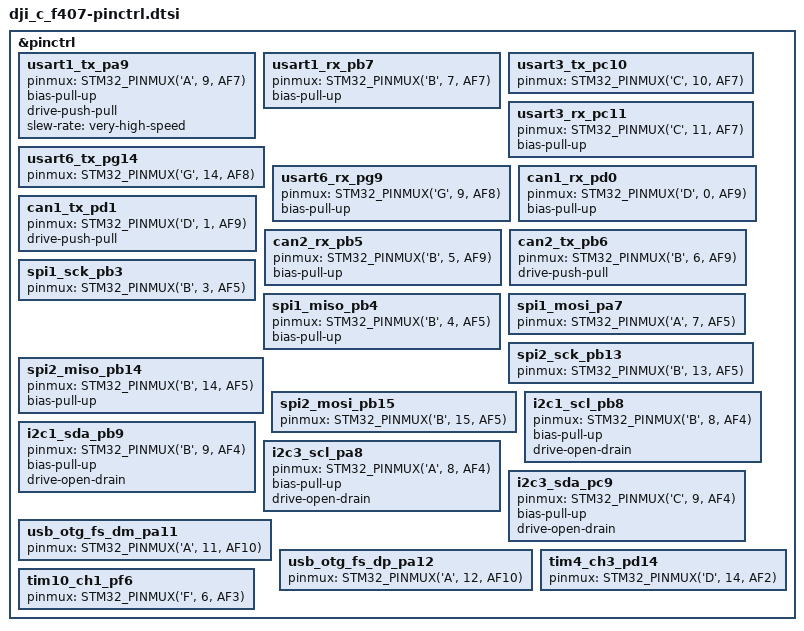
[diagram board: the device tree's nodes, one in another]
/* SPDX-License-Identifier: Apache-2.0 */

#include <zephyr/dt-bindings/pinctrl/stm32-pinctrl.h>

&pinctrl {
	usart1_tx_pa9: usart1_tx_pa9 {
		pinmux = <STM32_PINMUX('A', 9, AF7)>;
		bias-pull-up;
		drive-push-pull;
		slew-rate = "very-high-speed";
	};

	usart1_rx_pb7: usart1_rx_pb7 {
		pinmux = <STM32_PINMUX('B', 7, AF7)>;
		bias-pull-up;
	};

	usart3_tx_pc10: usart3_tx_pc10 { pinmux = <STM32_PINMUX('C', 10, AF7)>; };
	usart3_rx_pc11: usart3_rx_pc11 { pinmux = <STM32_PINMUX('C', 11, AF7)>; bias-pull-up; };
	usart6_tx_pg14: usart6_tx_pg14 { pinmux = <STM32_PINMUX('G', 14, AF8)>; };
	usart6_rx_pg9: usart6_rx_pg9 { pinmux = <STM32_PINMUX('G', 9, AF8)>; bias-pull-up; };

	can1_rx_pd0: can1_rx_pd0 { pinmux = <STM32_PINMUX('D', 0, AF9)>; bias-pull-up; };
	can1_tx_pd1: can1_tx_pd1 { pinmux = <STM32_PINMUX('D', 1, AF9)>; drive-push-pull; };
	can2_rx_pb5: can2_rx_pb5 { pinmux = <STM32_PINMUX('B', 5, AF9)>; bias-pull-up; };
	can2_tx_pb6: can2_tx_pb6 { pinmux = <STM32_PINMUX('B', 6, AF9)>; drive-push-pull; };

	spi1_sck_pb3: spi1_sck_pb3 { pinmux = <STM32_PINMUX('B', 3, AF5)>; };
	spi1_miso_pb4: spi1_miso_pb4 { pinmux = <STM32_PINMUX('B', 4, AF5)>; bias-pull-up; };
	spi1_mosi_pa7: spi1_mosi_pa7 { pinmux = <STM32_PINMUX('A', 7, AF5)>; };
	spi2_sck_pb13: spi2_sck_pb13 { pinmux = <STM32_PINMUX('B', 13, AF5)>; };
	spi2_miso_pb14: spi2_miso_pb14 { pinmux = <STM32_PINMUX('B', 14, AF5)>; bias-pull-up; };
	spi2_mosi_pb15: spi2_mosi_pb15 { pinmux = <STM32_PINMUX('B', 15, AF5)>; };

	i2c1_scl_pb8: i2c1_scl_pb8 { pinmux = <STM32_PINMUX('B', 8, AF4)>; bias-pull-up; drive-open-drain; };
	i2c1_sda_pb9: i2c1_sda_pb9 { pinmux = <STM32_PINMUX('B', 9, AF4)>; bias-pull-up; drive-open-drain; };
	i2c3_scl_pa8: i2c3_scl_pa8 { pinmux = <STM32_PINMUX('A', 8, AF4)>; bias-pull-up; drive-open-drain; };
	i2c3_sda_pc9: i2c3_sda_pc9 { pinmux = <STM32_PINMUX('C', 9, AF4)>; bias-pull-up; drive-open-drain; };

	usb_otg_fs_dm_pa11: usb_otg_fs_dm_pa11 { pinmux = <STM32_PINMUX('A', 11, AF10)>; };
	usb_otg_fs_dp_pa12: usb_otg_fs_dp_pa12 { pinmux = <STM32_PINMUX('A', 12, AF10)>; };
	tim4_ch3_pd14: tim4_ch3_pd14 { pinmux = <STM32_PINMUX('D', 14, AF2)>; };
	tim10_ch1_pf6: tim10_ch1_pf6 { pinmux = <STM32_PINMUX('F', 6, AF3)>; };
};
